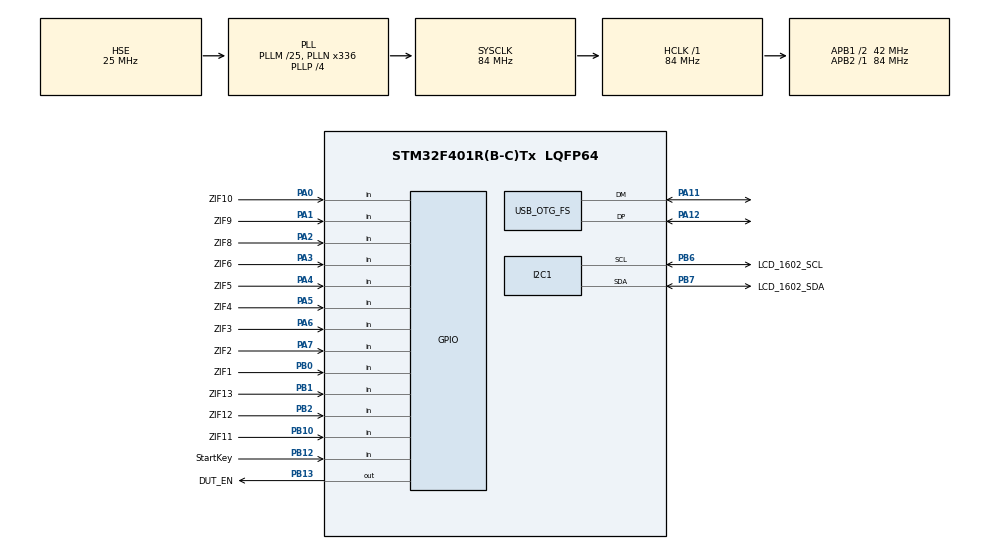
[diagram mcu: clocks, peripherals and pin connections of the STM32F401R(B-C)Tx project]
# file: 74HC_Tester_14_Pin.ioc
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Mcu.Family=STM32F4
Mcu.Name=STM32F401R(B-C)Tx
Mcu.Package=LQFP64
NVIC.OTG_FS_IRQn=true\:0\:0\:false\:false\:true\:false\:true\:true
NVIC.PriorityGroup=NVIC_PRIORITYGROUP_4
NVIC.TIM1_BRK_TIM9_IRQn=true\:15\:0\:false\:false\:true\:false\:true\:true
NVIC.TimeBase=TIM1_BRK_TIM9_IRQn
NVIC.TimeBaseIP=TIM9
PA0-WKUP.GPIO_Label=ZIF10
PA0-WKUP.GPIO_PuPd=GPIO_PULLDOWN
PA0-WKUP.Signal=GPIO_Input
PA1.GPIO_Label=ZIF9
PA1.GPIO_PuPd=GPIO_PULLDOWN
PA1.Signal=GPIO_Input
PA11.Mode=Device_Only
PA11.Signal=USB_OTG_FS_DM
PA12.Mode=Device_Only
PA12.Signal=USB_OTG_FS_DP
PA13.Mode=Serial_Wire
PA13.Signal=SYS_JTMS-SWDIO
PA14.Mode=Serial_Wire
PA14.Signal=SYS_JTCK-SWCLK
PA2.GPIO_Label=ZIF8
PA2.GPIO_Mode=GPIO_MODE_INPUT
PA2.GPIO_PuPd=GPIO_PULLDOWN
PA2.Signal=GPIO_Input
PA3.GPIO_Label=ZIF6
PA3.GPIO_Mode=GPIO_MODE_INPUT
PA3.GPIO_PuPd=GPIO_PULLDOWN
PA3.Signal=GPIO_Input
PA4.GPIO_Label=ZIF5
PA4.GPIO_PuPd=GPIO_PULLDOWN
PA4.Signal=GPIO_Input
PA5.GPIO_Label=ZIF4
PA5.GPIO_PuPd=GPIO_PULLDOWN
PA5.Signal=GPIO_Input
PA6.GPIO_Label=ZIF3
PA6.GPIO_PuPd=GPIO_PULLDOWN
PA6.Signal=GPIO_Input
PA7.GPIO_Label=ZIF2
PA7.GPIO_PuPd=GPIO_PULLDOWN
PA7.Signal=GPIO_Input
PB0.GPIO_Label=ZIF1
PB0.GPIO_PuPd=GPIO_PULLDOWN
PB0.Signal=GPIO_Input
PB1.GPIO_Label=ZIF13
PB1.GPIO_PuPd=GPIO_PULLDOWN
PB1.Signal=GPIO_Input
PB10.GPIO_Label=ZIF11
PB10.GPIO_PuPd=GPIO_PULLDOWN
PB10.Signal=GPIO_Input
PB12.GPIO_Label=StartKey
PB12.GPIO_PuPd=GPIO_PULLUP
PB12.Signal=GPIO_Input
PB13.GPIO_Label=DUT_EN
PB13.GPIO_ModeDefaultOutputPP=GPIO_MODE_OUTPUT_OD
PB13.PinState=GPIO_PIN_SET
PB13.Signal=GPIO_Output
PB2.GPIO_Label=ZIF12
PB2.GPIO_PuPd=GPIO_PULLDOWN
PB2.Signal=GPIO_Input
PB6.GPIO_Label=LCD_1602_SCL
PB6.Mode=I2C
PB6.Signal=I2C1_SCL
PB7.GPIO_Label=LCD_1602_SDA
PB7.Mode=I2C
PB7.Signal=I2C1_SDA
PH0\ -\ OSC_IN.Mode=HSE-External-Oscillator
PH0\ -\ OSC_IN.Signal=RCC_OSC_IN
PH1\ -\ OSC_OUT.Mode=HSE-External-Oscillator
PH1\ -\ OSC_OUT.Signal=RCC_OSC_OUT
ProjectManager.HeapSize=0x200
ProjectManager.StackSize=0x400
ProjectManager.TargetToolchain=STM32CubeIDE
RCC.48MHZClocksFreq_Value=48000000
RCC.AHBFreq_Value=84000000
RCC.APB1CLKDivider=RCC_HCLK_DIV2
RCC.APB1Freq_Value=42000000
RCC.APB1TimFreq_Value=84000000
RCC.APB2Freq_Value=84000000
RCC.APB2TimFreq_Value=84000000
RCC.CortexFreq_Value=84000000
RCC.HCLKFreq_Value=84000000
RCC.HSE_VALUE=25000000
RCC.HSI_VALUE=16000000
RCC.LSE_VALUE=32768
RCC.PLLM=25
RCC.PLLN=336
RCC.PLLP=RCC_PLLP_DIV4
RCC.PLLQ=7
RCC.SYSCLKFreq_VALUE=84000000
RCC.SYSCLKSource=RCC_SYSCLKSOURCE_PLLCLK
RCC.VCOOutputFreq_Value=336000000
USB_DEVICE.CLASS_NAME_FS=CDC
USB_DEVICE.VirtualMode=Cdc
USB_DEVICE.VirtualModeFS=Cdc_FS
USB_OTG_FS.VirtualMode=Device_Only
VP_SYS_VS_tim9.Mode=TIM9
VP_USB_DEVICE_VS_USB_DEVICE_CDC_FS.Mode=CDC_FS
board=custom

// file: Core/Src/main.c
/* USER CODE BEGIN Header */
/**
  ******************************************************************************
  * @file           : main.c
  * @brief          : Main program body
  ******************************************************************************
  * @attention
  *
  * Copyright (c) 2026 STMicroelectronics.
  * All rights reserved.
  *
  * This software is licensed under terms that can be found in the LICENSE file
  * in the root directory of this software component.
  * If no LICENSE file comes with this software, it is provided AS-IS.
  *
  ******************************************************************************
  */
/* USER CODE END Header */
#include "main.h"
#include "usb_device.h"

/* USER CODE BEGIN Includes */
#include "hc_tester.h"

/* USER CODE END Includes */

I2C_HandleTypeDef hi2c1;

void SystemClock_Config(void);
static void MX_GPIO_Init(void);
static void MX_I2C1_Init(void);

int main(void)
{

  /* MCU Configuration--------------------------------------------------------*/

  /* Reset of all peripherals, Initializes the Flash interface and the Systick. */
  HAL_Init();

  /* Configure the system clock */
  SystemClock_Config();

  /* Initialize all configured peripherals */
  MX_GPIO_Init();
  MX_I2C1_Init();
  MX_USB_DEVICE_Init();
  /* USER CODE BEGIN 2 */
  HC_Tester_Init();

  /* USER CODE END 2 */

  /* Infinite loop */
  while (1)
  {

    /* USER CODE BEGIN 3 */
    HC_Tester_Poll();
  }
  /* USER CODE END 3 */
}

void SystemClock_Config(void)
{
  RCC_OscInitTypeDef RCC_OscInitStruct = {0};
  RCC_ClkInitTypeDef RCC_ClkInitStruct = {0};

  /** Configure the main internal regulator output voltage
  */
  __HAL_RCC_PWR_CLK_ENABLE();
  __HAL_PWR_VOLTAGESCALING_CONFIG(PWR_REGULATOR_VOLTAGE_SCALE2);

  /** Initializes the RCC Oscillators according to the specified parameters
  * in the RCC_OscInitTypeDef structure.
  */
  RCC_OscInitStruct.OscillatorType = RCC_OSCILLATORTYPE_HSE;
  RCC_OscInitStruct.HSEState = RCC_HSE_ON;
  RCC_OscInitStruct.PLL.PLLState = RCC_PLL_ON;
  RCC_OscInitStruct.PLL.PLLSource = RCC_PLLSOURCE_HSE;
  RCC_OscInitStruct.PLL.PLLM = 25;
  RCC_OscInitStruct.PLL.PLLN = 336;
  RCC_OscInitStruct.PLL.PLLP = RCC_PLLP_DIV4;
  RCC_OscInitStruct.PLL.PLLQ = 7;
  if (HAL_RCC_OscConfig(&RCC_OscInitStruct) != HAL_OK)
  {
    Error_Handler();
  }

  /** Initializes the CPU, AHB and APB buses clocks
  */
  RCC_ClkInitStruct.ClockType = RCC_CLOCKTYPE_HCLK|RCC_CLOCKTYPE_SYSCLK
                              |RCC_CLOCKTYPE_PCLK1|RCC_CLOCKTYPE_PCLK2;
  RCC_ClkInitStruct.SYSCLKSource = RCC_SYSCLKSOURCE_PLLCLK;
  RCC_ClkInitStruct.AHBCLKDivider = RCC_SYSCLK_DIV1;
  RCC_ClkInitStruct.APB1CLKDivider = RCC_HCLK_DIV2;
  RCC_ClkInitStruct.APB2CLKDivider = RCC_HCLK_DIV1;

  if (HAL_RCC_ClockConfig(&RCC_ClkInitStruct, FLASH_LATENCY_2) != HAL_OK)
  {
    Error_Handler();
  }
}

static void MX_I2C1_Init(void)
{

  hi2c1.Instance = I2C1;
  hi2c1.Init.ClockSpeed = 100000;
  hi2c1.Init.DutyCycle = I2C_DUTYCYCLE_2;
  hi2c1.Init.OwnAddress1 = 0;
  hi2c1.Init.AddressingMode = I2C_ADDRESSINGMODE_7BIT;
  hi2c1.Init.DualAddressMode = I2C_DUALADDRESS_DISABLE;
  hi2c1.Init.OwnAddress2 = 0;
  hi2c1.Init.GeneralCallMode = I2C_GENERALCALL_DISABLE;
  hi2c1.Init.NoStretchMode = I2C_NOSTRETCH_DISABLE;
  if (HAL_I2C_Init(&hi2c1) != HAL_OK)
  {
    Error_Handler();
  }

}

static void MX_GPIO_Init(void)
{
  GPIO_InitTypeDef GPIO_InitStruct = {0};

  /* GPIO Ports Clock Enable */
  __HAL_RCC_GPIOH_CLK_ENABLE();
  __HAL_RCC_GPIOA_CLK_ENABLE();
  __HAL_RCC_GPIOB_CLK_ENABLE();

  /*Configure GPIO pins : ZIF10_Pin ZIF9_Pin ZIF8_Pin ZIF6_Pin
                           ZIF5_Pin ZIF4_Pin ZIF3_Pin ZIF2_Pin */
  GPIO_InitStruct.Pin = ZIF10_Pin|ZIF9_Pin|ZIF8_Pin|ZIF6_Pin
                          |ZIF5_Pin|ZIF4_Pin|ZIF3_Pin|ZIF2_Pin;
  GPIO_InitStruct.Mode = GPIO_MODE_INPUT;
  GPIO_InitStruct.Pull = GPIO_PULLDOWN;
  HAL_GPIO_Init(GPIOA, &GPIO_InitStruct);

  /*Configure GPIO pins : ZIF1_Pin ZIF13_Pin ZIF12_Pin ZIF11_Pin */
  GPIO_InitStruct.Pin = ZIF1_Pin|ZIF13_Pin|ZIF12_Pin|ZIF11_Pin;
  GPIO_InitStruct.Mode = GPIO_MODE_INPUT;
  GPIO_InitStruct.Pull = GPIO_PULLDOWN;
  HAL_GPIO_Init(GPIOB, &GPIO_InitStruct);

  HAL_GPIO_WritePin(DUT_EN_GPIO_Port, DUT_EN_Pin, GPIO_PIN_SET);
  GPIO_InitStruct.Pin = DUT_EN_Pin;
  GPIO_InitStruct.Mode = GPIO_MODE_OUTPUT_OD;
  GPIO_InitStruct.Pull = GPIO_NOPULL;
  GPIO_InitStruct.Speed = GPIO_SPEED_FREQ_LOW;
  HAL_GPIO_Init(DUT_EN_GPIO_Port, &GPIO_InitStruct);

  /*Configure GPIO pin : StartKey_Pin */
  GPIO_InitStruct.Pin = StartKey_Pin;
  GPIO_InitStruct.Mode = GPIO_MODE_INPUT;
  GPIO_InitStruct.Pull = GPIO_PULLUP;
  HAL_GPIO_Init(StartKey_GPIO_Port, &GPIO_InitStruct);

}

void HAL_TIM_PeriodElapsedCallback(TIM_HandleTypeDef *htim)
{
  if (htim->Instance == TIM9)
  {
    HAL_IncTick();
  }
}

void Error_Handler(void)
{
  __disable_irq();
  while (1)
  {
  }
}
